# wiz16b8m4ct3_0_WIZ16B8M4CT3 register map
Vendor: Texas Instruments
Registers are 32-bit, read-write, reset 0x0 unless marked. A register's access mark holds for its fields unless they carry their own. Offsets are as the file gives them; [hi:lo] are bit positions.

## wiz16b8m4ct3_0_WIZ16B8M4CT3 (part 12 of 12)
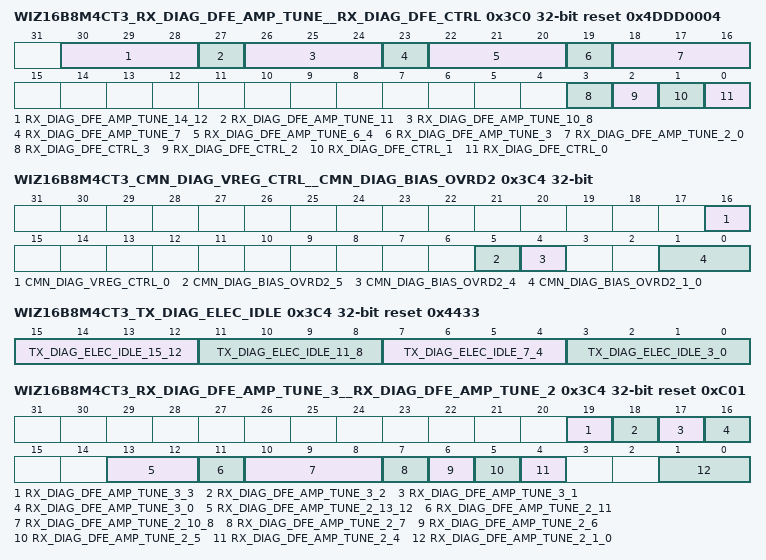
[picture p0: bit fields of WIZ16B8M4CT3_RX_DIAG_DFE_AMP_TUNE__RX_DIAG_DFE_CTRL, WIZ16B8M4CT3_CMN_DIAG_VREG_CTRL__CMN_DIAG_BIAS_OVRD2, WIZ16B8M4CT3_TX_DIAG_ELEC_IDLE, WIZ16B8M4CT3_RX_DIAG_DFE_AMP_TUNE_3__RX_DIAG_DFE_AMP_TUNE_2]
0x3C0 WIZ16B8M4CT3_RX_DIAG_DFE_AMP_TUNE__RX_DIAG_DFE_CTRL reset 0x4DDD0004
  [30:28] RX_DIAG_DFE_AMP_TUNE_14_12 — DFE constant gm bias tune: Adjusts the constant gm bias. 3'b000: -34 uA 3'b001 3'b010 3'b011 3'b100: - 50 uA 3'b101 3'b110 3'b111: -62 uA
  [27] RX_DIAG_DFE_AMP_TUNE_11 — DFE VGA constant gm bias enable: Enables the VGA constant gm bias. This bit drives the rxda_vga_cnst_gm_en signal going to the analog. 1'b0 : Disabled. 1'b1 : Enabled.
  [26:24] RX_DIAG_DFE_AMP_TUNE_10_8 — DFE VGA amp current adjust: Adjusts the current for the DFE VGA amp, using the rxda_vga_current_adj signal, as specified below. Note: The percentages are approximate values. 3'b000: +30% (maximum) ... 3'b101: 0% ... 3'b111: -30% (minimum)
  [23] RX_DIAG_DFE_AMP_TUNE_7 — DFE peaking constant gm bias enable: Enables the peaking constant gm bias. This bit drives the rxda_peak_cnst_gm_en signal going to the analog. 1'b0 : Disabled. 1'b1 : Enabled.
  [22:20] RX_DIAG_DFE_AMP_TUNE_6_4 — DFE peaking amp current adjust: Adjusts the current for the DFE peaking amp, using the rxda_peak_current_adj signal, as specified below. Note: The percentages are approximate values. 3'b000: +30% (maximum) ... 3'b101: 0% ... 3'b111: -30% (minimum)
  [19] RX_DIAG_DFE_AMP_TUNE_3 — DFE summing constant gm bias enable: Enables the summing constant gm bias. This bit drives the rxda_sum_cnst_gm_en signal going to the analog. 1'b0 : Disabled. 1'b1 : Enabled.
  [18:16] RX_DIAG_DFE_AMP_TUNE_2_0 — DFE summing amp current adjust: Adjusts the current for the DFE summing amp, using the rxda_sum_current_adj signal, as specified below. Note: The percentages are approximate values. 3'b000: +30% (maximum) ... 3'b101: 0% ... 3'b111: -30% (minimum)
  [3] RX_DIAG_DFE_CTRL_3 — Receiver DFE low frequency equalization enable value standard mode 3: This bit controls the rxda_dfe_lfeq_en signal going to the analog, which is used to enable the receiver DFE low frequency equalization analog circuits, when xcvr_standard_mode is set to 2'b11. 1'b0 : Disabled 1'b1 : Enabled
  [2] RX_DIAG_DFE_CTRL_2 — Receiver DFE low frequency equalization enable value standard mode 2: This bit controls the rxda_dfe_lfeq_en signal going to the analog, which is used to enable the receiver DFE low frequency equalization analog circuits, when xcvr_standard_mode is set to 2'b10. 1'b0 : Disabled 1'b1 : Enabled
  [1] RX_DIAG_DFE_CTRL_1 — Receiver DFE low frequency equalization enable value standard mode 1: This bit controls the rxda_dfe_lfeq_en signal going to the analog, which is used to enable the receiver DFE low frequency equalization analog circuits, when xcvr_standard_mode is set to 2'b01. 1'b0 : Disabled 1'b1 : Enabled
  [0] RX_DIAG_DFE_CTRL_0 — Receiver DFE low frequency equalization enable value standard mode 0: This bit controls the rxda_dfe_lfeq_en signal going to the analog, which is used to enable the receiver DFE low frequency equalization analog circuits, when xcvr_standard_mode is set to 2'b00. 1'b0 : Disabled 1'b1 : Enabled
0x3C4 WIZ16B8M4CT3_CMN_DIAG_VREG_CTRL__CMN_DIAG_BIAS_OVRD2
  [16] CMN_DIAG_VREG_CTRL_0 — Voltage regulator reference voltage select: Selects the reference voltage used for the voltage regulator in common, by driving the cmnda_vreg_ref_sel signal to the analog. 1'b0: Bandgap supply 1'b1: Core supply
  [5] CMN_DIAG_BIAS_OVRD2_5 — Bias filter bypass enable override enable: When active (1'b1), the bias filter bypass enable override bit in this register, can be used to directly control the bias filter bypass enable function.
  [4] CMN_DIAG_BIAS_OVRD2_4 — Bias filter bypass enable override: When enabled by the bias filter bypass enable override enable bit in this register, this bit will directly control the bias filter bypass enable function.
  [1:0] CMN_DIAG_BIAS_OVRD2_1_0 — Regulator bandgap reference voltage adjust: This field is used to adjust the regulator bandgap reference voltage, by driving the cmnda_bias_vreg_adj signal to the analog. The encoding of this field is as follows. 2'b00 : 850 mV 2'b01 : 830 mV 2'b10 : 810 mV 2'b11 : Reserved
0x3C4 WIZ16B8M4CT3_TX_DIAG_ELEC_IDLE reset 0x4433
  [15:12] TX_DIAG_ELEC_IDLE_15_12 — TX electrical idle exit delay 16 bit data width : This field controls the amount of additional delay added to the electrical idle signal after the sync FIFO, when exiting the electrical idle state for 16 bit data width modes. The valid values that can be used for this field are the same as those in the TX electrical idle entry delay 20 bit data width field of this register.
  [11:8] TX_DIAG_ELEC_IDLE_11_8 — TX electrical idle entry delay 16 bit data width : This field controls the amount of additional delay added to the electrical idle signal after the sync FIFO, when entering the electrical idle state for 16 bit data width modes. The valid values that can be used for this field are the same as those in the TX electrical idle entry delay 20 bit data width field of this register.
  [7:4] TX_DIAG_ELEC_IDLE_7_4 — TX electrical idle exit delay 20 bit data width : This field controls the amount of additional delay added to the electrical idle signal after the sync FIFO, when exiting the electrical idle state for 20 bit data width modes. The valid values that can be used for this field are the same as those in the TX electrical idle entry delay 20 bit data width field of this register.
  [3:0] TX_DIAG_ELEC_IDLE_3_0 — TX electrical idle entry delay 20 bit data width : This field controls the amount of additional delay added to the electrical idle signal after the sync FIFO, when entering the electrical idle state for 20 bit data width modes. The following are the valid values that can be used for this field, and the corresponding delays. Note: In the cases of 1/2 clock cycle delays, this is implemented on the falling edge of the clock, so the result is a function of the duty cycle of the clock. 4'b0000 : Reserved. 4'b0001 : Reserved. 4'b0010 : 1.0 clock delays. 4'b0011 : 1.5 clock delays. 4'b0100 : 2.0 clock delays. 4'b0101 : 2.5 clock delays. 4'b0110 : 3.0 clock delays. 4'b0111 : 3.5 clock delays. 4'b1000 : 4.0 clock delays. 4'b1001 : 4.5 clock delays. 4'b1010 : 5.0 clock delays. 4'b1011 : 5.5 clock delays. 4'b1100 : 6.0 clock delays. 4'b1101 : 6.5 clock delays. 4'b1110 : 7.0 clock delays. 4'b1111 : 7.5 clock delays.
0x3C4 WIZ16B8M4CT3_RX_DIAG_DFE_AMP_TUNE_3__RX_DIAG_DFE_AMP_TUNE_2 reset 0xC01
  [19] RX_DIAG_DFE_AMP_TUNE_3_3 — DFE VGA stage 1 active inductor boost enable standard mode 3: This bit enables the active inductors boost function in stage 1 of the VGA, for high data rates, when xcvr_standard_mode is set to 2'b11. This bit controls the rxda_vga_st1_actind_en signal going to the analog. 1'b0 : Disabled 1'b1 : Enabled
  [18] RX_DIAG_DFE_AMP_TUNE_3_2 — DFE VGA stage 1 active inductor boost enable standard mode 2: This bit enables the active inductors boost function in stage 1 of the VGA, for high data rates, when xcvr_standard_mode is set to 2'b10. This bit controls the rxda_vga_st1_actind_en signal going to the analog. 1'b0 : Disabled 1'b1 : Enabled
  [17] RX_DIAG_DFE_AMP_TUNE_3_1 — DFE VGA stage 1 active inductor boost enable standard mode 1: This bit enables the active inductors boost function in stage 1 of the VGA, for high data rates, when xcvr_standard_mode is set to 2'b01. This bit controls the rxda_vga_st1_actind_en signal going to the analog. 1'b0 : Disabled 1'b1 : Enabled
  [16] RX_DIAG_DFE_AMP_TUNE_3_0 — DFE VGA stage 1 active inductor boost enable standard mode 0: This bit enables the active inductors boost function in stage 1 of the VGA, for high data rates, when xcvr_standard_mode is set to 2'b00. This bit controls the rxda_vga_st1_actind_en signal going to the analog. 1'b0 : Disabled 1'b1 : Enabled
  [13:12] RX_DIAG_DFE_AMP_TUNE_2_13_12 — Receiver peaking amp common mode adjust: Adjusts the common mode voltage for the receiver peaking amp, by driving the rxda_fe_pkamp_cm_adj signal to the analog. 2'b00 : Nominal common mode voltage. 2'b01 : Reduces the common mode voltage by one step. 2'b10 : Increases the common mode voltage by one step. 2'b11 : Reserved
  [11] RX_DIAG_DFE_AMP_TUNE_2_11 — DFE low frequency equalizer constant gm bias enable: Enables the low frequency equalizer constant gm bias. This bit drives the rxda_lfeq_cnst_gm_en signal going to the analog. 1'b0 : Disabled. 1'b1 : Enabled.
  [10:8] RX_DIAG_DFE_AMP_TUNE_2_10_8 — DFE low frequency equalizer current adjust: Adjusts the current for the DFE low frequency equalizer, using the rxda_lfeq_current_adj signal, as specified below. Note: The percentages are approximate values. 3'b000: +30% (maximum) ... 3'b101: 0% ... 3'b111: -30% (minimum)
  [7] RX_DIAG_DFE_AMP_TUNE_2_7 — DFE peaking amp active inductor boost: Enables the active inductors boost function in the peaking amp, for high data rates. This bit controls the rxda_peak_actind_en signal going to the analog. 1'b0 : Disabled 1'b1 : Enabled
  [6] RX_DIAG_DFE_AMP_TUNE_2_6 — Reserved - Spare
  [5] RX_DIAG_DFE_AMP_TUNE_2_5 — DFE VGA stage 2 active inductor boost: Enables the active inductors boost function in stage 2 of the VGA, for high data rates. This bit controls the rxda_vga_st2_actind_en signal going to the analog. 1'b0 : Disabled 1'b1 : Enabled
  [4] RX_DIAG_DFE_AMP_TUNE_2_4 — DFE RX Tap 1 DAC Range Select: Controls the tap 1 DAC range in the analog DFE. This bit controls the rxda_dfe_tap_1_range signal going to the analog. 1'b0: Normal operation 1'b1: The tap 1 DAC range is increased.
  [1:0] RX_DIAG_DFE_AMP_TUNE_2_1_0 — DFE RX amp current adjust: Adjusts the mix of constant-gm and External Current for RX front end amplifiers. This controls the rxda_cnstgm_ext_sel signal going into the analog. The encoding of the rxda_cnstgm_ext_sel signal, as a function of the values in this register is specified below. 2'b00 =X 3'b000 : gm_bias = 25u, ext = 25u, total = 50u 2'b01 =X 3'b001 : gm_bias = 30u, ext = 20u, total = 50u 2'b10 =X 3'b011 : gm_bias = 35u, ext = 15u, total = 50u 2'b11 =X 3'b111 : gm_bias = 40u, ext = 10u, total = 50u
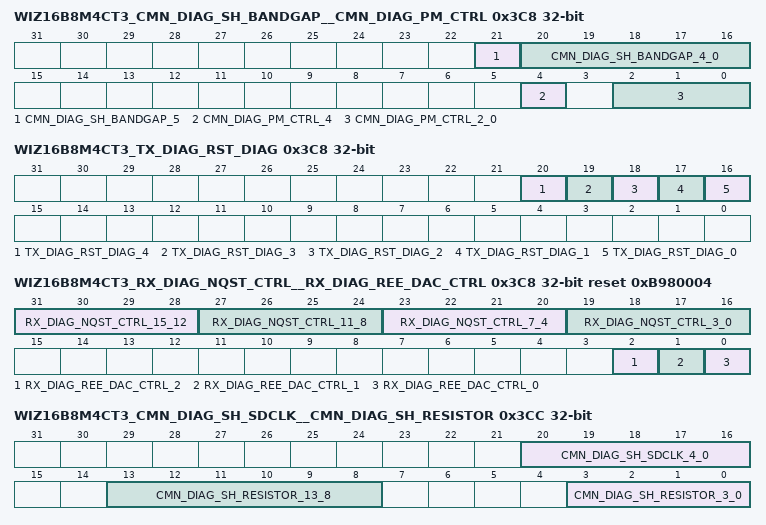
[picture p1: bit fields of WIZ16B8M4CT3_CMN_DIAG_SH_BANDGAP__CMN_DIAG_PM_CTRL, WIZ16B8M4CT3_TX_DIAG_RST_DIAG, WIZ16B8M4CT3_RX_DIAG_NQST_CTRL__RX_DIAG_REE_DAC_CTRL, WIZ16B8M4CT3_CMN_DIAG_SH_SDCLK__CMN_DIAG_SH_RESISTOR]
0x3C8 WIZ16B8M4CT3_CMN_DIAG_SH_BANDGAP__CMN_DIAG_PM_CTRL access per field
  [21] CMN_DIAG_SH_BANDGAP_5 ro — Bandgap up value: Bandgap calibration up signal value, as it is currently captured in the sample and hold latches.
  [20:16] CMN_DIAG_SH_BANDGAP_4_0 ro — Bandgap auto zero select value: Bandgap calibration auto zero select signal value, as it is currently captured in the sample and hold latches.
  [4] CMN_DIAG_PM_CTRL_4 rw — Process monitor enable: Enables the analog process monitor, by driving the cmnda_pcm_en signal to the analog. 1'b0: Disabled 1'b1: Enabled
  [2:0] CMN_DIAG_PM_CTRL_2_0 rw — Process monitor mode select: Selects the mode of the analog process monitor, by driving the cmnda_pcm_sel signal to the analog. 000 : SVT 11nm oscillator, 001 : LVT 11nm oscillator, 010 : ULVT 11nm oscillator, 011 : IO oscillator, 100 : SVT 36nm oscillator, 101 : LVT 36nm oscillator, 110 : ULVT 36nm oscillator, 111 : Reserved
0x3C8 WIZ16B8M4CT3_TX_DIAG_RST_DIAG ro
  [20] TX_DIAG_RST_DIAG_4 — Current state of the txda_tx_clk_reset_n reset.
  [19] TX_DIAG_RST_DIAG_3 — Current state of the tx_dig_reset_n reset.
  [18] TX_DIAG_RST_DIAG_2 — Current state of the tx_sync_fifo_deq_rst_n reset.
  [17] TX_DIAG_RST_DIAG_1 — Current state of the tx_sync_fifo_enq_rst_n reset.
  [16] TX_DIAG_RST_DIAG_0 — Current state of the tx_lfps_reset_n reset.
0x3C8 WIZ16B8M4CT3_RX_DIAG_NQST_CTRL__RX_DIAG_REE_DAC_CTRL reset 0xB980004
  [31:28] RX_DIAG_NQST_CTRL_15_12 — RX nyquist select value standard mode 3: This field specifies the receiver DFE nyquist frequency select value on the rxda_dfe_nqst_sel signal driven to the analog, when xcvr_standard_mode is set to 2'b11.
  [27:24] RX_DIAG_NQST_CTRL_11_8 — RX nyquist select value standard mode 2: This field specifies the receiver DFE nyquist frequency select value on the rxda_dfe_nqst_sel signal driven to the analog, when xcvr_standard_mode is set to 2'b10.
  [23:20] RX_DIAG_NQST_CTRL_7_4 — RX nyquist select value standard mode 1: This field specifies the receiver DFE nyquist frequency select value on the rxda_dfe_nqst_sel signal driven to the analog, when xcvr_standard_mode is set to 2'b01.
  [19:16] RX_DIAG_NQST_CTRL_3_0 — RX nyquist select value standard mode 0: This field specifies the receiver DFE nyquist frequency select value on the rxda_dfe_nqst_sel signal driven to the analog, when xcvr_standard_mode is set to 2'b00.
  [2] RX_DIAG_REE_DAC_CTRL_2 — DFE Offset DAC enable: Enables the DFE offset DAC associated with the VGA amp. 1'b0: Disabled. 1'b1: Enabled.
  [1] RX_DIAG_REE_DAC_CTRL_1 — DFE Offset DAC attenuation: Adds attenuation to the DFE offset DAC associated with the VGA amp. 1'b0: No attenuation. 1'b1: DAC gain attenuated by 40%.
  [0] RX_DIAG_REE_DAC_CTRL_0 — DFE DAC attenuation: Adds attenuation to the DFE DACs associated with the summing amp. 1'b0: No attenuation. 1'b1: DAC gain attenuated by 30%.
0x3CC WIZ16B8M4CT3_CMN_DIAG_SH_SDCLK__CMN_DIAG_SH_RESISTOR ro
  [20:16] CMN_DIAG_SH_SDCLK_4_0 — Signal detect clock code: Signal detect clock calibration code signal value, as it is currently captured in the sample and hold latches.
  [13:8] CMN_DIAG_SH_RESISTOR_13_8 — TX resistor code: TX resistor calibration code signal value, as it is currently captured in the sample and hold latches.
  [3:0] CMN_DIAG_SH_RESISTOR_3_0 — RX resistor code: RX resistor calibration code signal value, as it is currently captured in the sample and hold latches.
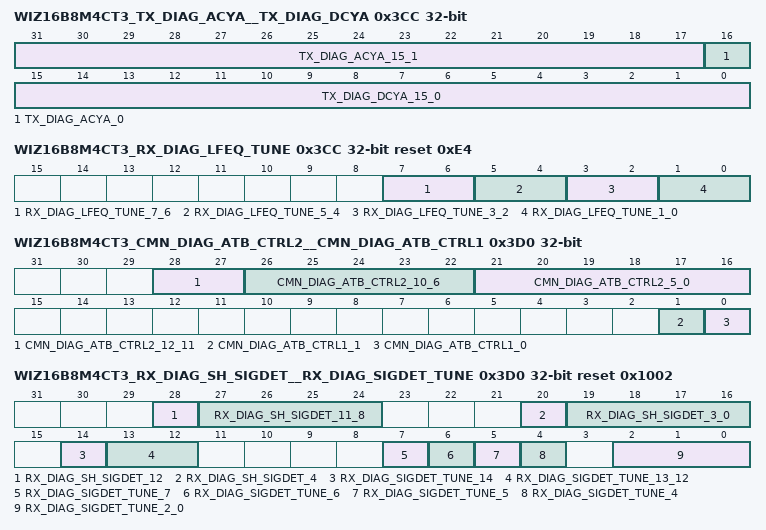
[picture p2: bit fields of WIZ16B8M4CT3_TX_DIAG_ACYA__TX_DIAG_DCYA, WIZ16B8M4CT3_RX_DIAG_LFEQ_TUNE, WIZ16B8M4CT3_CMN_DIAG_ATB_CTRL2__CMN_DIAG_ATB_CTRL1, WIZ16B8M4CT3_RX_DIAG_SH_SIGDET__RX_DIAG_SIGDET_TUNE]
0x3CC WIZ16B8M4CT3_TX_DIAG_ACYA__TX_DIAG_DCYA
  [31:17] TX_DIAG_ACYA_15_1 — Reserved - spare
  [16] TX_DIAG_ACYA_0 — HBDC latch control: Controls the state of the latches associated with the H bridge driver controller related signals in the H bridge driver encoder logic digital in the transmitter analog, as well as the boost enable and level control signals. These latches can be closed to hold the current state of these signals. While closed, the signals that drive the latch inputs can be changed by writing the registers that control them, and not effect the state of the driver. Once such register writes are complete, the latches can be made transparent again to apply the changes. 1'b0: Latches transparent 1'b1: Latches gated
  [15:0] TX_DIAG_DCYA_15_0 — Reserved - spare
0x3CC WIZ16B8M4CT3_RX_DIAG_LFEQ_TUNE reset 0xE4
  [7:6] RX_DIAG_LFEQ_TUNE_7_6 — RX low frequency equalization zero frequency value standard mode 3: This field specifies the receiver zero frequency setting for the low frequency equalization function, by thermometer encoding the value of this field and driving it on the rxda_dfe_lfeq_zero_freq signal going into the analog, when xcvr_standard_mode is set to 2'b11. The following is the encoding of this field. 2'b00 : 150 MHz 2'b01 : 200 MHz 2'b10 : 250 MHz 2'b11 : 300 MHz
  [5:4] RX_DIAG_LFEQ_TUNE_5_4 — RX low frequency equalization zero frequency value standard mode 2: This field specifies the receiver zero frequency setting for the low frequency equalization function, by thermometer encoding the value of this field and driving it on the rxda_dfe_lfeq_zero_freq signal going into the analog, when xcvr_standard_mode is set to 2'b10. The following is the encoding of this field. 2'b00 : 150 MHz 2'b01 : 200 MHz 2'b10 : 250 MHz 2'b11 : 300 MHz
  [3:2] RX_DIAG_LFEQ_TUNE_3_2 — RX low frequency equalization zero frequency value standard mode 1: This field specifies the receiver zero frequency setting for the low frequency equalization function, by thermometer encoding the value of this field and driving it on the rxda_dfe_lfeq_zero_freq signal going into the analog, when xcvr_standard_mode is set to 2'b01. The following is the encoding of this field. 2'b00 : 150 MHz 2'b01 : 200 MHz 2'b10 : 250 MHz 2'b11 : 300 MHz
  [1:0] RX_DIAG_LFEQ_TUNE_1_0 — RX low frequency equalization zero frequency value standard mode 0: This field specifies the receiver zero frequency setting for the low frequency equalization function, by thermometer encoding the value of this field and driving it on the rxda_dfe_lfeq_zero_freq signal going into the analog, when xcvr_standard_mode is set to 2'b00. The following is the encoding of this field. 2'b00 : 150 MHz 2'b01 : 200 MHz 2'b10 : 250 MHz 2'b11 : 300 MHz
0x3D0 WIZ16B8M4CT3_CMN_DIAG_ATB_CTRL2__CMN_DIAG_ATB_CTRL1
  [28:27] CMN_DIAG_ATB_CTRL2_12_11 — ATB component type select: These bits specify which component type is currently selected by the ATB, as specified below. 2'b00: Common 2'b01: Transmitter 2'b10: Receiver 2'b11: Reserved
  [26:22] CMN_DIAG_ATB_CTRL2_10_6 — ATB component sub address: Specifies the sub address of the component being selected. In this design, the sub address must be 0 when accessing the common, and the lane number when accessing a transmitter or receiver.
  [21:16] CMN_DIAG_ATB_CTRL2_5_0 — ATB test point address: Specifies the exact point in the selected analog component to be observed.
  [1] CMN_DIAG_ATB_CTRL1_1 — Core side ATB enable: When active (1'b) and the ATB enable bit in this register is also active, the ATB signals will be driven on the core side ATB signals.
  [0] CMN_DIAG_ATB_CTRL1_0 — ATB enable: When active (1'b1), the ATB test function is enabled.
0x3D0 WIZ16B8M4CT3_RX_DIAG_SH_SIGDET__RX_DIAG_SIGDET_TUNE access per field reset 0x1002
  [28] RX_DIAG_SH_SIGDET_12 ro — Signal detect 1 up: Signal detect 1 calibration up signal value, as it is currently captured in the sample and hold latches.
  [27:24] RX_DIAG_SH_SIGDET_11_8 ro — Signal detect 1 code: Signal detect 1 calibration code signal value, as it is currently captured in the sample and hold latches.
  [20] RX_DIAG_SH_SIGDET_4 ro — Signal detect 0 up: Signal detect 0 calibration up signal value, as it is currently captured in the sample and hold latches.
  [19:16] RX_DIAG_SH_SIGDET_3_0 ro — Signal detect 0 code: Signal detect 0 calibration code signal value, as it is currently captured in the sample and hold latches.
  [14] RX_DIAG_SIGDET_TUNE_14 rw — Signal detect calibration half gain select: Controls the resolution of each step in the signal detect calibration code by adjusting the gain of signal detect offset correction, by driving the rxda_sd_cal_halfgain signal going to the analog, as specified below. 1'b0: 8mV resolution per calibration code step. 1'b1: 4mV resolution per calibration code step.
  [13:12] RX_DIAG_SIGDET_TUNE_13_12 rw — Signal detect filter function select: Selects which of the two RX signal detect filter functions are enabled. As specified below. 2'b00 : Reserved 2'b01 : RX low to high filter disabled, RX high to low filter enabled. 2'b10 : RX low to high filter enabled, RX high to low filter disabled. 2'b11 : RX low to high filter enabled, RX high to low filter enabled.
  [7] RX_DIAG_SIGDET_TUNE_7 rw — Receiver signal detect invert samplers: Inverts the behavior of the rxda_sd_pulse_high and rxda_sd_pulse_low samplers, by driving the rxda_sd_invert_samplers signal to the analog. 1'b0 : Normal mode : The rxda_sd_pulse_high sampler outputs a 1'b1 if the output of the comparator has been above the positive threshold at any time during the last clock period. Similar behavior exists for the rxda_sd_pulse_low sampler in this mode. 1'b1 : Inverted mode : The rxda_sd_pulse_high sampler outputs a 1'b1 if the output of the comparator has been above the positive threshold for the entire duration of the last clock period. Similar behavior exists for the rxda_sd_pulse_low sampler in this mode.
  [6] RX_DIAG_SIGDET_TUNE_6 rw — Receiver signal detect squelch pulse none: Enable the squelch function for the rxda_sd_pulse_none signal, by driving the rxda_sd_squelch_pulse_none signal to the analog. This debug feature could allow the detection of LFPS signals having slow transition times (e.g. 4 nSec) and low frequency differential noise (e.g. 500 MHz). The later can create noise glitches taking place over man than 1/2 cycle when DCD is taken into consideration. 1'b0 : Disabled 1'b1 : Enabled
  [5] RX_DIAG_SIGDET_TUNE_5 rw — Receiver signal detect one comparator mode: Enables one comparator mode, as a power reduction option, by driving the rxda_sd_onecomp_mode_en signal to the analog. 1'b0 : Both signal detect comparators functioning. 1'b1 : One signal detect comparator functioning.
  [4] RX_DIAG_SIGDET_TUNE_4 rw — Receiver signal detect DC coupled path enable: Enables a DC coupled path to the signal detect for verification and testability purposes, by driving the rxda_sd_dcpath_en signal to the analog. 1'b0 : Disabled 1'b1 : Enabled
  [2:0] RX_DIAG_SIGDET_TUNE_2_0 rw — Signal detect level: Sets the reference voltage level at which the comparators will detect a signal by driving the rxda_sd_siglvl_n signal going to the analog. The following specifies the encoding of this signal. 3'b000 : 8'b11111110 : Min 3'b001 : 8'b11111101 ... 3'b110 : 8'b10111111 3'b111 : 8'b01111111 : Max
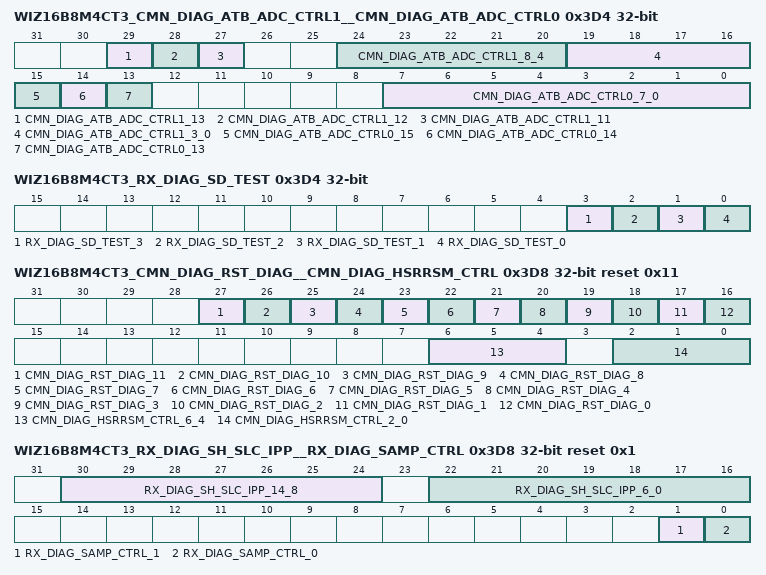
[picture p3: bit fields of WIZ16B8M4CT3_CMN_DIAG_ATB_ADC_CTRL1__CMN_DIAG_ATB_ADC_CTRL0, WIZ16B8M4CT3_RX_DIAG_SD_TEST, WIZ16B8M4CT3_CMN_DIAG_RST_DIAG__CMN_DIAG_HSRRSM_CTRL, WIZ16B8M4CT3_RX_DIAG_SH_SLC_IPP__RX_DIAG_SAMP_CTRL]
0x3D4 WIZ16B8M4CT3_CMN_DIAG_ATB_ADC_CTRL1__CMN_DIAG_ATB_ADC_CTRL0 access per field
  [29] CMN_DIAG_ATB_ADC_CTRL1_13 rw — ATB ADC offset correction enable : Enables internal auto generated offset correction mode, by driving the cmnda_atba2d_en_off_cor signal to the analog. 1'b0: Disabled 1'b1: Enabled
  [28] CMN_DIAG_ATB_ADC_CTRL1_12 rw — ATB ADC force cap values : Forces a positive or negative voltage on the internal cap, by driving the cmnda_atba2d_frc_val signal to the analog. 1'b0: Forces a negative voltage on the cap. 1'b1: Forces a positive voltage on the cap.
  [27] CMN_DIAG_ATB_ADC_CTRL1_11 rw — ATB ADC enable manual offset correction : When this signal is active, the value in the ATB ADC manual offset correction value field of this register is used to manually control the offset correction, by driving the cmnda_atba2d_off_byp_en signal to the analog. 1'b0: Disabled 1'b1: Enabled
  [24:20] CMN_DIAG_ATB_ADC_CTRL1_8_4 rw — ATB ADC manual offset correction value : When the ATB ADC enable manual offset correction bit in this register is active, this field is used to manually control the offset correction, by driving the cmnda_atba2d_off_adj_byp signal to the analog.
  [19:16] CMN_DIAG_ATB_ADC_CTRL1_3_0 rw — ATB ADC mode : This field indicates the mode the analog to digital converter is in. This field directly controls the cmnda_atba2d_adcmode signal going to the analog. For current mode measurements (ATB analog to digital converter mode == 3'b101), the current is equal to (Code/256)*0.6901/10.5K uA. The following list describes each of the modes, and the value used to select it. 4'b0000: Hi-Z Mode 4'b0001: atb0 and local gnd 4'b0010: atb0 assumed remote gnd 4'b0011: atb1 and local gnd 4'b0100: atb1 assumed remote gnd 4'b0101: 10K between atb0 and agnd 4'b0110: Offset Measure Mode volt offset 4'b0111: Offset Measure Mode current offset 4'b1000: BIST mode - force cap 1 polarity based on the ADC force cap values bit in this register. 4'b1001: BIST mode - force cap 2 polarity based on the ADC force cap values bit in this register. 4'b1010: BIST mode - force cap 3 polarity based on the ADC force cap values bit in this register. 4'b1011: BIST mode - force cap 4 polarity based on the ADC force cap values bit in this register. 4'b1100: BIST mode - force cap 5 polarity based on the ADC force cap values bit in this register. 4'b1101: BIST mode - force cap 6 polarity based on the ADC force cap values bit in this register. 4'b1110: BIST mode - force cap 7 polarity based on the ADC force cap values bit in this register. 4'b1111: BIST mode - force cap 8 polarity based on the ADC force cap values bit in this register. BIST mode procedure:
  [15] CMN_DIAG_ATB_ADC_CTRL0_15 rw — ATB analog ADC enable: This enables the analog ADC function, by driving the cmnda_atba2d_en signal to the analog. This bit must be set to the enabled state before starting an ATB ADC process using the other bits in this register. 1'b0: ADC disabled 1'b1: ADC enabled
  [14] CMN_DIAG_ATB_ADC_CTRL0_14 rw — Start ATB ADC process: Activating (1'b1) this bit will start the ATB ADC process. This signal must remain active until the ATB ADC process is complete, as indicated by the ATB ADC process done bit in this register. To start another ATB ADC process, this bit must first be deactivated until the ATB ADC process done bit in this register is also cleared. This bit drives the cmnda_atba2d_start signal to the analog.
  [13] CMN_DIAG_ATB_ADC_CTRL0_13 ro — ATB ADC process done: This bit will be set to 1'b1 when the ATB ADC process is complete, and the data in the ATB ADC code field of this register is considered valid. Once set to 1'b1, it will remain set until the Start ATB ADC process bit in this register is set to 1'b0. This bit is driven by the cmnda_atba2d_dvalid signal from the analog.
  [7:0] CMN_DIAG_ATB_ADC_CTRL0_7_0 ro — ATB ADC data code: This is the digital code representing the level of the analog ATB signal that was digitized by the analog ADC. This code is only valid when the ATB ADC process done bit in this register is active (1'b1). The voltage represented by this value is equal to code/256*0.94.
0x3D4 WIZ16B8M4CT3_RX_DIAG_SD_TEST
  [3] RX_DIAG_SD_TEST_3 — LFPS detected low test bit: This bit can be used to detect if the rx_lfps_detect is driven to a low state. The following procedure can be used to detect this condition. Write this bit to a 1'b1. Read this bit. If the value of the read bit is 1'b0, rx_lfps_detect is driven to a low state between the write and the read. Note: If rx_lfps_detect is already driven to a low state at the time of the write, the bit will not be set to 1'b1.
  [2] RX_DIAG_SD_TEST_2 — LFPS detected high test bit: This bit can be used to detect if the rx_lfps_detect is driven to a high state. The following procedure can be used to detect this condition. Write this bit to a 1'b1. Read this bit. If the value of the read bit is 1'b0, rx_lfps_detect is driven to a high state between the write and the read. Note: If rx_lfps_detect is already driven to a high state at the time of the write, the bit will not be set to 1'b1.
  [1] RX_DIAG_SD_TEST_1 — Signal detected low test bit: This bit can be used to detect if the rx_signal_detect is driven to a low state. The following procedure can be used to detect this condition. Write this bit to a 1'b1. Read this bit. If the value of the read bit is 1'b0, rx_signal_detect is driven to a low state between the write and the read. Note: If rx_signal_detect is already driven to a low state at the time of the write, the bit will not be set to 1'b1.
  [0] RX_DIAG_SD_TEST_0 — Signal detected high test bit: This bit can be used to detect if the rx_signal_detect is driven to a high state. The following procedure can be used to detect this condition. Write this bit to a 1'b1. Read this bit. If the value of the read bit is 1'b0, rx_signal_detect is driven to a high state between the write and the read. Note: If rx_signal_detect is already driven to a high state at the time of the write, the bit will not be set to 1'b1.
0x3D8 WIZ16B8M4CT3_CMN_DIAG_RST_DIAG__CMN_DIAG_HSRRSM_CTRL access per field reset 0x11
  [27] CMN_DIAG_RST_DIAG_11 ro — Current state of the cmn_sd_clk_cal_fb_clk_reset_n reset.
  [26] CMN_DIAG_RST_DIAG_10 ro — Current state of the cmn_sd_clk_cal_ref_clk_reset_n reset.
  [25] CMN_DIAG_RST_DIAG_9 ro — Current state of the cmn_pll1_dsm_reset_n reset.
  [24] CMN_DIAG_RST_DIAG_8 ro — Current state of the cmn_pll0_dsm_reset_n reset.
  [23] CMN_DIAG_RST_DIAG_7 ro — Current state of the cmn_pll1_vco_cal_fbdiv_clk_reset_n reset.
  [22] CMN_DIAG_RST_DIAG_6 ro — Current state of the cmn_pll1_lock_det_fbdiv_clk_reset_n reset.
  [21] CMN_DIAG_RST_DIAG_5 ro — Current state of the cmn_pll1_vco_cal_ref_clk_reset_n reset.
  [20] CMN_DIAG_RST_DIAG_4 ro — Current state of the cmn_pll1_lock_det_ref_clk_reset_n reset.
  [19] CMN_DIAG_RST_DIAG_3 ro — Current state of the cmn_pll0_vco_cal_fbdiv_clk_reset_n reset.
  [18] CMN_DIAG_RST_DIAG_2 ro — Current state of the cmn_pll0_lock_det_fbdiv_clk_reset_n reset.
  [17] CMN_DIAG_RST_DIAG_1 ro — Current state of the cmn_pll0_vco_cal_ref_clk_reset_n reset.
  [16] CMN_DIAG_RST_DIAG_0 ro — Current state of the cmn_pll0_lock_det_ref_clk_reset_n reset.
  [6:4] CMN_DIAG_HSRRSM_CTRL_6_4 rw — Transceiver reset delay : Species the number of PSM clock cycles the transceiver common high speed reset state machine stays in the delay state.
  [2:0] CMN_DIAG_HSRRSM_CTRL_2_0 rw — Transmitter reset delay : Species the number of PSM clock cycles the transmitter common high speed reset state machine stays in the delay state.
0x3D8 WIZ16B8M4CT3_RX_DIAG_SH_SLC_IPP__RX_DIAG_SAMP_CTRL access per field reset 0x1
  [30:24] RX_DIAG_SH_SLC_IPP_14_8 ro — RX sampler latch calibration I even positive code: RX sampler latch calibration I even positive code signal value, as it is currently captured in the sample and hold latches.
  [22:16] RX_DIAG_SH_SLC_IPP_6_0 ro — RX sampler latch calibration I odd positive code: RX sampler latch calibration I odd positive code signal value, as it is currently captured in the sample and hold latches.
  [1] RX_DIAG_SAMP_CTRL_1 rw — RX sampler latch range extend: Controls the range of the RX sampler calibration, by driving the rxda_sampler_latch_cal_range_ext signal to the analog. 1'b0 : Normal range 1'b1 : Extended range (adds approximately 1.4 mV per step or 21 mV total.)
  [0] RX_DIAG_SAMP_CTRL_0 rw — Analog sampler rxda_dfe_0p5ui_mode_en signal control: Selects which delayed I data is to be used to unroll the Q data in the sampler. 1'b0: The I data that occurs 1.5 UI before the Q data is used to select the proper Q sample. 1'b1: The I data that occurs 0.5 UI before the corresponding Q data is used to select the proper Q sample. Note: The signal controlled by this register is forced to 1'b0 when RX sampler latch calibration is running.
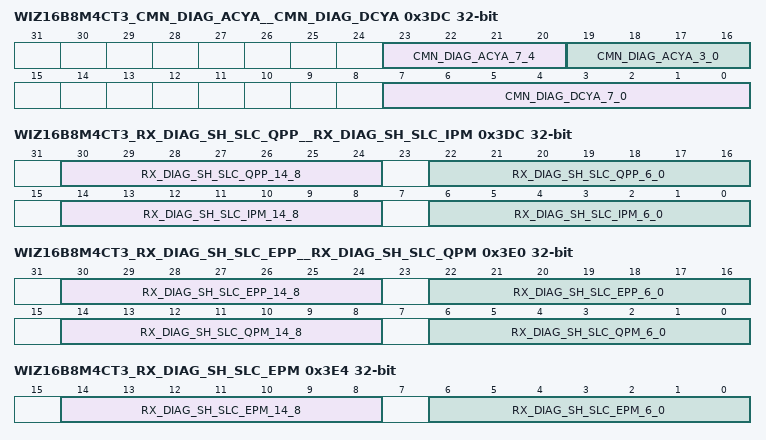
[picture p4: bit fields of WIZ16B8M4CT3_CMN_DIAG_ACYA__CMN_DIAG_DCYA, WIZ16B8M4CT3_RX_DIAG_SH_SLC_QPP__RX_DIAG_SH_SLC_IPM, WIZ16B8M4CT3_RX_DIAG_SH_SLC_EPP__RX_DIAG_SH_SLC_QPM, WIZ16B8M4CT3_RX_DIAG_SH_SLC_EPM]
0x3DC WIZ16B8M4CT3_CMN_DIAG_ACYA__CMN_DIAG_DCYA
  [23:20] CMN_DIAG_ACYA_7_4 — Reserved - spare
  [19:16] CMN_DIAG_ACYA_3_0 — PLL charge pump proportional gain adjust: Adjusts the charge pump gain for the PLLs to help manage bandwidth. The following is the encoding of this field. 4'b0000: vctrip + 0 mV 4'b0001: vctrip + 15 mV 4'b0011: vctrip + 30 mV 4'b0111: vctrip + 45 mV 4'b1111: vctrip + 60 mV
  [7:0] CMN_DIAG_DCYA_7_0 — Reserved - spare
0x3DC WIZ16B8M4CT3_RX_DIAG_SH_SLC_QPP__RX_DIAG_SH_SLC_IPM ro
  [30:24] RX_DIAG_SH_SLC_QPP_14_8 — RX sampler latch calibration Q even positive code: RX sampler latch calibration Q even positive code signal value, as it is currently captured in the sample and hold latches.
  [22:16] RX_DIAG_SH_SLC_QPP_6_0 — RX sampler latch calibration Q odd positive code: RX sampler latch calibration Q odd positive code signal value, as it is currently captured in the sample and hold latches.
  [14:8] RX_DIAG_SH_SLC_IPM_14_8 — RX sampler latch calibration I even negative code: RX sampler latch calibration I even negative code signal value, as it is currently captured in the sample and hold latches.
  [6:0] RX_DIAG_SH_SLC_IPM_6_0 — RX sampler latch calibration I odd negative code: RX sampler latch calibration I odd negative code signal value, as it is currently captured in the sample and hold latches.
0x3E0 WIZ16B8M4CT3_RX_DIAG_SH_SLC_EPP__RX_DIAG_SH_SLC_QPM ro
  [30:24] RX_DIAG_SH_SLC_EPP_14_8 — RX sampler latch calibration E even positive code: RX sampler latch calibration E even positive code signal value, as it is currently captured in the sample and hold latches.
  [22:16] RX_DIAG_SH_SLC_EPP_6_0 — RX sampler latch calibration E odd positive code: RX sampler latch calibration E odd positive code signal value, as it is currently captured in the sample and hold latches.
  [14:8] RX_DIAG_SH_SLC_QPM_14_8 — RX sampler latch calibration Q even negative code: RX sampler latch calibration Q even negative code signal value, as it is currently captured in the sample and hold latches.
  [6:0] RX_DIAG_SH_SLC_QPM_6_0 — RX sampler latch calibration Q odd negative code: RX sampler latch calibration Q odd negative code signal value, as it is currently captured in the sample and hold latches.
0x3E4 WIZ16B8M4CT3_RX_DIAG_SH_SLC_EPM ro
  [14:8] RX_DIAG_SH_SLC_EPM_14_8 — RX sampler latch calibration E even negative code: RX sampler latch calibration E even negative code signal value, as it is currently captured in the sample and hold latches.
  [6:0] RX_DIAG_SH_SLC_EPM_6_0 — RX sampler latch calibration E odd negative code: RX sampler latch calibration E odd negative code signal value, as it is currently captured in the sample and hold latches.
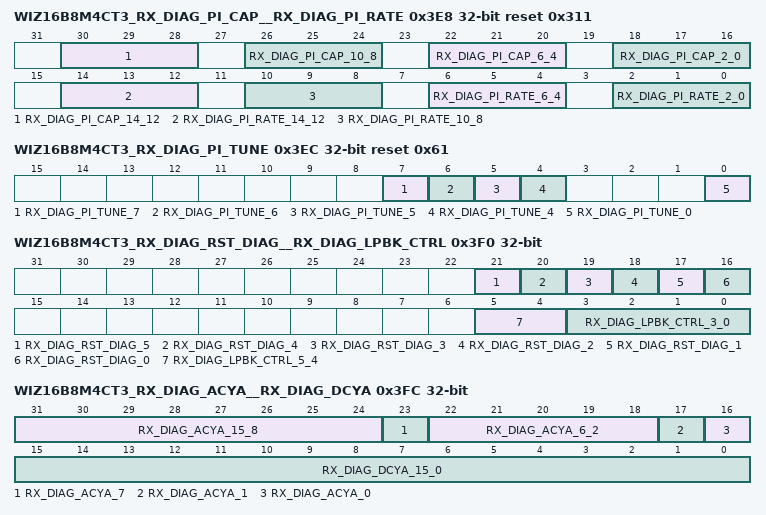
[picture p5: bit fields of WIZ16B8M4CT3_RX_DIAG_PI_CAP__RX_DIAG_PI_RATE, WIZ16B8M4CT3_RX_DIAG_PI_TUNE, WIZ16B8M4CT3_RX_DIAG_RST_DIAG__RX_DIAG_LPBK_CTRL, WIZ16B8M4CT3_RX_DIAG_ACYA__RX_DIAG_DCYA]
0x3E8 WIZ16B8M4CT3_RX_DIAG_PI_CAP__RX_DIAG_PI_RATE reset 0x311
  [30:28] RX_DIAG_PI_CAP_14_12 — PI capacitor selection standard mode 3: This field is used to implement waveform shaping inside the PI CML cells, by changing the capacitive loading. As the data rate decreases, this is used to increase cap loading, to maintain semi-sinusoidal wave shapes inside the PI CML input buffers and mixers, by driving the rxda_pi_cap_sel signal going into the analog, when xcvr_standard_mode is set to 2'b11. The following is the encoding of this field. 3'b000: Data rates X 1.25 Gbps 3'b001: Data rates X= 1.25 Gbps 3'b010 - 3'b111: Reserved
  [26:24] RX_DIAG_PI_CAP_10_8 — PI capacitor selection standard mode 2: This field is used to implement waveform shaping inside the PI CML cells, by changing the capacitive loading. As the data rate decreases, this is used to increase cap loading, to maintain semi-sinusoidal wave shapes inside the PI CML input buffers and mixers, by driving the rxda_pi_cap_sel signal going into the analog, when xcvr_standard_mode is set to 2'b10. The following is the encoding of this field. 3'b000: Data rates X 1.25 Gbps 3'b001: Data rates X= 1.25 Gbps 3'b010 - 3'b111: Reserved
  [22:20] RX_DIAG_PI_CAP_6_4 — PI capacitor selection standard mode 1: This field is used to implement waveform shaping inside the PI CML cells, by changing the capacitive loading. As the data rate decreases, this is used to increase cap loading, to maintain semi-sinusoidal wave shapes inside the PI CML input buffers and mixers, by driving the rxda_pi_cap_sel signal going into the analog, when xcvr_standard_mode is set to 2'b01. The following is the encoding of this field. 3'b000: Data rates X 1.25 Gbps 3'b001: Data rates X= 1.25 Gbps 3'b010 - 3'b111: Reserved
  [18:16] RX_DIAG_PI_CAP_2_0 — PI capacitor selection standard mode 0: This field is used to implement waveform shaping inside the PI CML cells, by changing the capacitive loading. As the data rate decreases, this is used to increase cap loading, to maintain semi-sinusoidal wave shapes inside the PI CML input buffers and mixers, by driving the rxda_pi_cap_sel signal going into the analog, when xcvr_standard_mode is set to 2'b00. The following is the encoding of this field. 3'b000: Data rates X 1.25 Gbps 3'b001: Data rates X= 1.25 Gbps 3'b010 - 3'b111: Reserved
  [14:12] RX_DIAG_PI_RATE_14_12 — PI rate selection standard mode 3: This field is used to scale the power of the CML cells inside the PI to tune it for a given data rate, by driving the rxda_pi_rate_sel signal going into the analog, when xcvr_standard_mode is set to 2'b11. The following is the encoding of this field. 3'b000: 1/2X power scaling for the CML cells. This should be the default setting for 2.5G data rates. 3'b001:1X power scaling for the CML cells. This should be the default setting for 5G data rates. 3'b010: Reserved 3'b011: 2X power scaling for the CML cells. This should be the default setting for 10G data rates. 3'b100 - 3'b111: Reserved
  [10:8] RX_DIAG_PI_RATE_10_8 — PI rate selection standard mode 2: This field is used to scale the power of the CML cells inside the PI to tune it for a given data rate, by driving the rxda_pi_rate_sel signal going into the analog, when xcvr_standard_mode is set to 2'b10. The following is the encoding of this field. 3'b000: 1/2X power scaling for the CML cells. This should be the default setting for 2.5G data rates. 3'b001:1X power scaling for the CML cells. This should be the default setting for 5G data rates. 3'b010: Reserved 3'b011: 2X power scaling for the CML cells. This should be the default setting for 10G data rates. 3'b100 - 3'b111: Reserved
  [6:4] RX_DIAG_PI_RATE_6_4 — PI rate selection standard mode 1: This field is used to scale the power of the CML cells inside the PI to tune it for a given data rate, by driving the rxda_pi_rate_sel signal going into the analog, when xcvr_standard_mode is set to 2'b01. The following is the encoding of this field. 3'b000: 1/2X power scaling for the CML cells. This should be the default setting for 2.5G data rates. 3'b001:1X power scaling for the CML cells. This should be the default setting for 5G data rates. 3'b010: Reserved 3'b011: 2X power scaling for the CML cells. This should be the default setting for 10G data rates. 3'b100 - 3'b111: Reserved
  [2:0] RX_DIAG_PI_RATE_2_0 — PI rate selection standard mode 0: This field is used to scale the power of the CML cells inside the PI to tune it for a given data rate, by driving the rxda_pi_rate_sel signal going into the analog, when xcvr_standard_mode is set to 2'b00. The following is the encoding of this field. 3'b000: 1/2X power scaling for the CML cells. This should be the default setting for 2.5G data rates. 3'b001:1X power scaling for the CML cells. This should be the default setting for 5G data rates. 3'b010: Reserved 3'b011: 2X power scaling for the CML cells. This should be the default setting for 10G data rates. 3'b100 - 3'b111: Reserved
0x3EC WIZ16B8M4CT3_RX_DIAG_PI_TUNE reset 0x61
  [7] RX_DIAG_PI_TUNE_7 — Receiver CML to CMOS rate select value standard mode 3: This bit will drive the rxda_c2c_rate_sel signal going into the analog, when xcvr_standard_mode is set to 2'b11. 1'b0 : High resistance 1'b1 : Low resistance
  [6] RX_DIAG_PI_TUNE_6 — Receiver CML to CMOS rate select value standard mode 2: This bit will drive the rxda_c2c_rate_sel signal going into the analog, when xcvr_standard_mode is set to 2'b10. 1'b0 : High resistance 1'b1 : Low resistance
  [5] RX_DIAG_PI_TUNE_5 — Receiver CML to CMOS rate select value standard mode 1: This bit will drive the rxda_c2c_rate_sel signal going into the analog, when xcvr_standard_mode is set to 2'b01. 1'b0 : High resistance 1'b1 : Low resistance
  [4] RX_DIAG_PI_TUNE_4 — Receiver CML to CMOS rate select value standard mode 0: This bit will drive the rxda_c2c_rate_sel signal going into the analog, when xcvr_standard_mode is set to 2'b00. 1'b0 : High resistance 1'b1 : Low resistance
  [0] RX_DIAG_PI_TUNE_0 — PI current select: Selects either the external based bias or the poly based bias for the PI, by driving the rxda_pi_cur_sel signal going into the analog. 1'b0: Poly based bias 1'b1: External based bias
0x3F0 WIZ16B8M4CT3_RX_DIAG_RST_DIAG__RX_DIAG_LPBK_CTRL access per field
  [21] RX_DIAG_RST_DIAG_5 ro — Current state of the rxda_clk_reset_n reset.
  [20] RX_DIAG_RST_DIAG_4 ro — Current state of the rx_dig_reset_n reset.
  [19] RX_DIAG_RST_DIAG_3 ro — Current state of the rxda_cdrlf_reset_n reset.
  [18] RX_DIAG_RST_DIAG_2 ro — Current state of the rx_ree_fcn_reset_n reset.
  [17] RX_DIAG_RST_DIAG_1 ro — Current state of the rx_ree_ctrl_reset_n reset.
  [16] RX_DIAG_RST_DIAG_0 ro — Current state of the rx_lfps_det_filter_reset_n reset.
  [5:4] RX_DIAG_LPBK_CTRL_5_4 rw — Recovered clock loopback select: Selects which recovered clock to use when recovered clock loopback is enabled. 2'b00: I clock. 2'b01: Q clock 2'b10: E clock.
  [3:0] RX_DIAG_LPBK_CTRL_3_0 rw — Attenuation settings: Sets the attenuation for the ISI generation loopback filter, as specified below. 4'b0000 : 6 dB 4'b0001 ... 4'b0101 : 13 dB ... 4'b1000 : 16 dB ... 4'b1100 : 23 dB ... 4'b1101 4'b1110 : Highest attenuation 4'b1111 : High impedance
0x3FC WIZ16B8M4CT3_RX_DIAG_ACYA__RX_DIAG_DCYA
  [31:24] RX_DIAG_ACYA_15_8 — Reserved - spare
  [23] RX_DIAG_ACYA_7 — Serial loopback sampler setup time reduction select (TX only lane implementation): For TX only lane implementations, this bit can be used to reduce the setup time (providing more hold margin) for the serial loopback data. This function is in place, in case there are unexpected timing issues, due to the lack of a CDRLF in the transmit only lane implementations. 1'b0: Default setup time 1'b1: Reduced setup time
  [22:18] RX_DIAG_ACYA_6_2 — Reserved - spare
  [17] RX_DIAG_ACYA_1 — Force receiver signal detect clock enable: This bit is used to force the receiver signal detect clock (rxda_sd_clk) driven from the analog to be enabled, independent of whether the analog signal detect function is enabled or not. 1'b0: Clock not forced to be enabled 1'b1: Clock forced to be enabled
  [16] RX_DIAG_ACYA_0 — Full rate clock duty cycle correction enable: Enables the analog duty cycle correction function for the full rate clock that drives the divide by 2 circuit to generate the half rate I and Q clocks. 1'b0: Enabled 1'b1: Disabled
  [15:0] RX_DIAG_DCYA_15_0 — Reserved - spare
